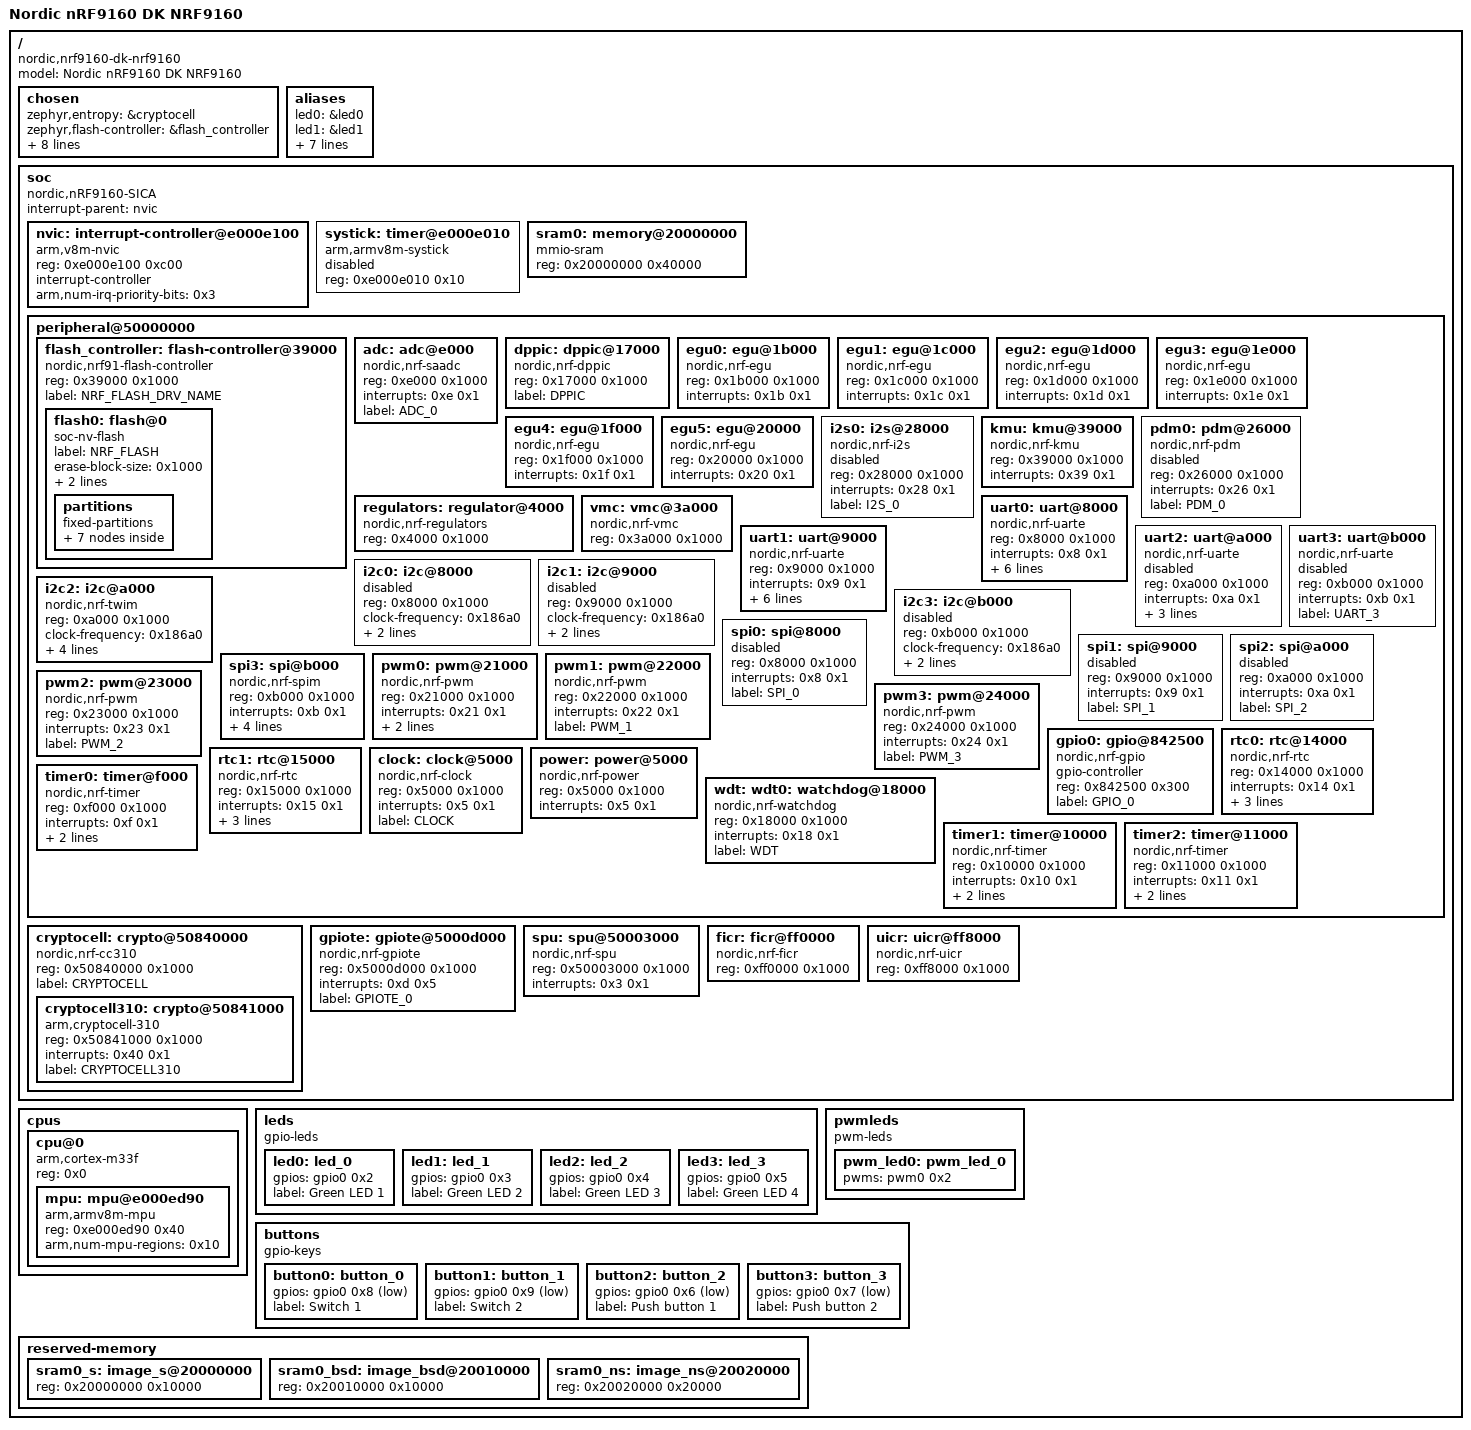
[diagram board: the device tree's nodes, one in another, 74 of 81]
/dts-v1/;

/ {
	#address-cells = < 0x1 >;
	#size-cells = < 0x1 >;
	model = "Nordic nRF9160 DK NRF9160";
	compatible = "nordic,nrf9160-dk-nrf9160";
	chosen {
		zephyr,entropy = &cryptocell;
		zephyr,flash-controller = &flash_controller;
		zephyr,console = &uart0;
		zephyr,shell-uart = &uart0;
		zephyr,uart-mcumgr = &uart0;
		zephyr,sram = &sram0_s;
		zephyr,flash = &flash0;
		zephyr,code-partition = &slot0_partition;
		zephyr,sram-secure-partition = &sram0_s;
		zephyr,sram-non-secure-partition = &sram0_ns;
	};
	aliases {
		led0 = &led0;
		led1 = &led1;
		led2 = &led2;
		led3 = &led3;
		pwm-led0 = &pwm_led0;
		sw0 = &button2;
		sw1 = &button3;
		sw2 = &button0;
		sw3 = &button1;
	};
	soc {
		#address-cells = < 0x1 >;
		#size-cells = < 0x1 >;
		compatible = "nordic,nRF9160-SICA", "nordic,nRF9160", "nordic,nRF91", "simple-bus";
		interrupt-parent = < &nvic >;
		ranges;
		nvic: interrupt-controller@e000e100 {
			compatible = "arm,v8m-nvic";
			reg = < 0xe000e100 0xc00 >;
			interrupt-controller;
			#interrupt-cells = < 0x2 >;
			arm,num-irq-priority-bits = < 0x3 >;
			phandle = < 0x1 >;
		};
		systick: timer@e000e010 {
			compatible = "arm,armv8m-systick";
			reg = < 0xe000e010 0x10 >;
			status = "disabled";
		};
		sram0: memory@20000000 {
			compatible = "mmio-sram";
			reg = < 0x20000000 0x40000 >;
		};
		peripheral@50000000 {
			#address-cells = < 0x1 >;
			#size-cells = < 0x1 >;
			ranges = < 0x0 0x50000000 0x10000000 >;
			flash_controller: flash-controller@39000 {
				compatible = "nordic,nrf91-flash-controller";
				reg = < 0x39000 0x1000 >;
				#address-cells = < 0x1 >;
				#size-cells = < 0x1 >;
				label = "NRF_FLASH_DRV_NAME";
				flash0: flash@0 {
					compatible = "soc-nv-flash";
					label = "NRF_FLASH";
					erase-block-size = < 0x1000 >;
					write-block-size = < 0x4 >;
					reg = < 0x0 0x100000 >;
					partitions {
						compatible = "fixed-partitions";
						#address-cells = < 0x1 >;
						#size-cells = < 0x1 >;
						boot_partition: partition@0 {
							label = "mcuboot";
							reg = < 0x0 0x10000 >;
						};
						slot0_partition: partition@10000 {
							label = "image-0";
							reg = < 0x10000 0x40000 >;
						};
						slot0_ns_partition: partition@50000 {
							label = "image-0-nonsecure";
							reg = < 0x50000 0x30000 >;
						};
						slot1_partition: partition@80000 {
							label = "image-1";
							reg = < 0x80000 0x40000 >;
						};
						slot1_ns_partition: partition@c0000 {
							label = "image-1-nonsecure";
							reg = < 0xc0000 0x30000 >;
						};
						scratch_partition: partition@f0000 {
							label = "image-scratch";
							reg = < 0xf0000 0xa000 >;
						};
						storage_partition: partition@fa000 {
							label = "storage";
							reg = < 0xfa000 0x6000 >;
						};
					};
				};
			};
			adc: adc@e000 {
				compatible = "nordic,nrf-saadc";
				reg = < 0xe000 0x1000 >;
				interrupts = < 0xe 0x1 >;
				status = "okay";
				label = "ADC_0";
				#io-channel-cells = < 0x1 >;
			};
			dppic: dppic@17000 {
				compatible = "nordic,nrf-dppic";
				reg = < 0x17000 0x1000 >;
				status = "okay";
				label = "DPPIC";
			};
			egu0: egu@1b000 {
				compatible = "nordic,nrf-egu";
				reg = < 0x1b000 0x1000 >;
				interrupts = < 0x1b 0x1 >;
				status = "okay";
			};
			egu1: egu@1c000 {
				compatible = "nordic,nrf-egu";
				reg = < 0x1c000 0x1000 >;
				interrupts = < 0x1c 0x1 >;
				status = "okay";
			};
			egu2: egu@1d000 {
				compatible = "nordic,nrf-egu";
				reg = < 0x1d000 0x1000 >;
				interrupts = < 0x1d 0x1 >;
				status = "okay";
			};
			egu3: egu@1e000 {
				compatible = "nordic,nrf-egu";
				reg = < 0x1e000 0x1000 >;
				interrupts = < 0x1e 0x1 >;
				status = "okay";
			};
			egu4: egu@1f000 {
				compatible = "nordic,nrf-egu";
				reg = < 0x1f000 0x1000 >;
				interrupts = < 0x1f 0x1 >;
				status = "okay";
			};
			egu5: egu@20000 {
				compatible = "nordic,nrf-egu";
				reg = < 0x20000 0x1000 >;
				interrupts = < 0x20 0x1 >;
				status = "okay";
			};
			i2s0: i2s@28000 {
				compatible = "nordic,nrf-i2s";
				#address-cells = < 0x1 >;
				#size-cells = < 0x0 >;
				reg = < 0x28000 0x1000 >;
				interrupts = < 0x28 0x1 >;
				status = "disabled";
				label = "I2S_0";
			};
			kmu: kmu@39000 {
				compatible = "nordic,nrf-kmu";
				reg = < 0x39000 0x1000 >;
				interrupts = < 0x39 0x1 >;
				status = "okay";
			};
			pdm0: pdm@26000 {
				compatible = "nordic,nrf-pdm";
				reg = < 0x26000 0x1000 >;
				interrupts = < 0x26 0x1 >;
				status = "disabled";
				label = "PDM_0";
			};
			regulators: regulator@4000 {
				compatible = "nordic,nrf-regulators";
				reg = < 0x4000 0x1000 >;
				status = "okay";
			};
			vmc: vmc@3a000 {
				compatible = "nordic,nrf-vmc";
				reg = < 0x3a000 0x1000 >;
				status = "okay";
			};
			uart0: uart@8000 {
				compatible = "nordic,nrf-uarte";
				reg = < 0x8000 0x1000 >;
				interrupts = < 0x8 0x1 >;
				status = "okay";
				label = "UART_0";
				current-speed = < 0x1c200 >;
				tx-pin = < 0x1d >;
				rx-pin = < 0x1c >;
				rts-pin = < 0x1b >;
				cts-pin = < 0x1a >;
			};
			uart1: uart@9000 {
				compatible = "nordic,nrf-uarte";
				reg = < 0x9000 0x1000 >;
				interrupts = < 0x9 0x1 >;
				status = "okay";
				label = "UART_1";
				current-speed = < 0x1c200 >;
				tx-pin = < 0x1 >;
				rx-pin = < 0x0 >;
				rts-pin = < 0xe >;
				cts-pin = < 0xf >;
			};
			uart2: uart@a000 {
				compatible = "nordic,nrf-uarte";
				reg = < 0xa000 0x1000 >;
				interrupts = < 0xa 0x1 >;
				status = "disabled";
				label = "UART_2";
				tx-pin = < 0x18 >;
				rx-pin = < 0x17 >;
			};
			uart3: uart@b000 {
				compatible = "nordic,nrf-uarte";
				reg = < 0xb000 0x1000 >;
				interrupts = < 0xb 0x1 >;
				status = "disabled";
				label = "UART_3";
			};
			i2c0: i2c@8000 {
				#address-cells = < 0x1 >;
				#size-cells = < 0x0 >;
				reg = < 0x8000 0x1000 >;
				clock-frequency = < 0x186a0 >;
				interrupts = < 0x8 0x1 >;
				status = "disabled";
				label = "I2C_0";
			};
			i2c1: i2c@9000 {
				#address-cells = < 0x1 >;
				#size-cells = < 0x0 >;
				reg = < 0x9000 0x1000 >;
				clock-frequency = < 0x186a0 >;
				interrupts = < 0x9 0x1 >;
				status = "disabled";
				label = "I2C_1";
			};
			i2c2: i2c@a000 {
				#address-cells = < 0x1 >;
				#size-cells = < 0x0 >;
				reg = < 0xa000 0x1000 >;
				clock-frequency = < 0x186a0 >;
				interrupts = < 0xa 0x1 >;
				status = "okay";
				label = "I2C_2";
				compatible = "nordic,nrf-twim";
				sda-pin = < 0x1e >;
				scl-pin = < 0x1f >;
			};
			i2c3: i2c@b000 {
				#address-cells = < 0x1 >;
				#size-cells = < 0x0 >;
				reg = < 0xb000 0x1000 >;
				clock-frequency = < 0x186a0 >;
				interrupts = < 0xb 0x1 >;
				status = "disabled";
				label = "I2C_3";
			};
			spi0: spi@8000 {
				#address-cells = < 0x1 >;
				#size-cells = < 0x0 >;
				reg = < 0x8000 0x1000 >;
				interrupts = < 0x8 0x1 >;
				status = "disabled";
				label = "SPI_0";
			};
			spi1: spi@9000 {
				#address-cells = < 0x1 >;
				#size-cells = < 0x0 >;
				reg = < 0x9000 0x1000 >;
				interrupts = < 0x9 0x1 >;
				status = "disabled";
				label = "SPI_1";
			};
			spi2: spi@a000 {
				#address-cells = < 0x1 >;
				#size-cells = < 0x0 >;
				reg = < 0xa000 0x1000 >;
				interrupts = < 0xa 0x1 >;
				status = "disabled";
				label = "SPI_2";
			};
			spi3: spi@b000 {
				#address-cells = < 0x1 >;
				#size-cells = < 0x0 >;
				reg = < 0xb000 0x1000 >;
				interrupts = < 0xb 0x1 >;
				status = "okay";
				label = "SPI_3";
				compatible = "nordic,nrf-spim";
				sck-pin = < 0x13 >;
				mosi-pin = < 0x12 >;
				miso-pin = < 0x11 >;
			};
			pwm0: pwm@21000 {
				compatible = "nordic,nrf-pwm";
				reg = < 0x21000 0x1000 >;
				interrupts = < 0x21 0x1 >;
				status = "okay";
				label = "PWM_0";
				#pwm-cells = < 0x1 >;
				ch0-pin = < 0x2 >;
				phandle = < 0x3 >;
			};
			pwm1: pwm@22000 {
				compatible = "nordic,nrf-pwm";
				reg = < 0x22000 0x1000 >;
				interrupts = < 0x22 0x1 >;
				status = "okay";
				label = "PWM_1";
				#pwm-cells = < 0x1 >;
			};
			pwm2: pwm@23000 {
				compatible = "nordic,nrf-pwm";
				reg = < 0x23000 0x1000 >;
				interrupts = < 0x23 0x1 >;
				status = "okay";
				label = "PWM_2";
				#pwm-cells = < 0x1 >;
			};
			pwm3: pwm@24000 {
				compatible = "nordic,nrf-pwm";
				reg = < 0x24000 0x1000 >;
				interrupts = < 0x24 0x1 >;
				status = "okay";
				label = "PWM_3";
				#pwm-cells = < 0x1 >;
			};
			gpio0: gpio@842500 {
				compatible = "nordic,nrf-gpio";
				gpio-controller;
				reg = < 0x842500 0x300 >;
				#gpio-cells = < 0x2 >;
				label = "GPIO_0";
				status = "okay";
				phandle = < 0x2 >;
			};
			rtc0: rtc@14000 {
				compatible = "nordic,nrf-rtc";
				reg = < 0x14000 0x1000 >;
				interrupts = < 0x14 0x1 >;
				status = "okay";
				clock-frequency = < 0x8000 >;
				prescaler = < 0x1 >;
				label = "RTC_0";
			};
			rtc1: rtc@15000 {
				compatible = "nordic,nrf-rtc";
				reg = < 0x15000 0x1000 >;
				interrupts = < 0x15 0x1 >;
				status = "okay";
				clock-frequency = < 0x8000 >;
				prescaler = < 0x1 >;
				label = "RTC_1";
			};
			clock: clock@5000 {
				compatible = "nordic,nrf-clock";
				reg = < 0x5000 0x1000 >;
				interrupts = < 0x5 0x1 >;
				status = "okay";
				label = "CLOCK";
			};
			power: power@5000 {
				compatible = "nordic,nrf-power";
				reg = < 0x5000 0x1000 >;
				interrupts = < 0x5 0x1 >;
				status = "okay";
			};
			wdt: wdt0: watchdog@18000 {
				compatible = "nordic,nrf-watchdog";
				reg = < 0x18000 0x1000 >;
				interrupts = < 0x18 0x1 >;
				status = "okay";
				label = "WDT";
			};
			timer0: timer@f000 {
				compatible = "nordic,nrf-timer";
				status = "okay";
				reg = < 0xf000 0x1000 >;
				interrupts = < 0xf 0x1 >;
				prescaler = < 0x0 >;
				label = "TIMER_0";
			};
			timer1: timer@10000 {
				compatible = "nordic,nrf-timer";
				status = "okay";
				reg = < 0x10000 0x1000 >;
				interrupts = < 0x10 0x1 >;
				prescaler = < 0x0 >;
				label = "TIMER_1";
			};
			timer2: timer@11000 {
				compatible = "nordic,nrf-timer";
				status = "okay";
				reg = < 0x11000 0x1000 >;
				interrupts = < 0x11 0x1 >;
				prescaler = < 0x0 >;
				label = "TIMER_2";
			};
		};
		cryptocell: crypto@50840000 {
			compatible = "nordic,nrf-cc310";
			reg = < 0x50840000 0x1000 >;
			label = "CRYPTOCELL";
			status = "okay";
			#address-cells = < 0x1 >;
			#size-cells = < 0x1 >;
			cryptocell310: crypto@50841000 {
				compatible = "arm,cryptocell-310";
				reg = < 0x50841000 0x1000 >;
				interrupts = < 0x40 0x1 >;
				label = "CRYPTOCELL310";
			};
		};
		gpiote: gpiote@5000d000 {
			compatible = "nordic,nrf-gpiote";
			reg = < 0x5000d000 0x1000 >;
			interrupts = < 0xd 0x5 >;
			status = "okay";
			label = "GPIOTE_0";
		};
		spu: spu@50003000 {
			compatible = "nordic,nrf-spu";
			reg = < 0x50003000 0x1000 >;
			interrupts = < 0x3 0x1 >;
			status = "okay";
		};
		ficr: ficr@ff0000 {
			compatible = "nordic,nrf-ficr";
			reg = < 0xff0000 0x1000 >;
			status = "okay";
		};
		uicr: uicr@ff8000 {
			compatible = "nordic,nrf-uicr";
			reg = < 0xff8000 0x1000 >;
			status = "okay";
		};
	};
	cpus {
		#address-cells = < 0x1 >;
		#size-cells = < 0x0 >;
		cpu@0 {
			device_type = "cpu";
			compatible = "arm,cortex-m33f";
			reg = < 0x0 >;
			#address-cells = < 0x1 >;
			#size-cells = < 0x1 >;
			mpu: mpu@e000ed90 {
				compatible = "arm,armv8m-mpu";
				reg = < 0xe000ed90 0x40 >;
				arm,num-mpu-regions = < 0x10 >;
			};
		};
	};
	leds {
		compatible = "gpio-leds";
		led0: led_0 {
			gpios = < &gpio0 0x2 0x0 >;
			label = "Green LED 1";
		};
		led1: led_1 {
			gpios = < &gpio0 0x3 0x0 >;
			label = "Green LED 2";
		};
		led2: led_2 {
			gpios = < &gpio0 0x4 0x0 >;
			label = "Green LED 3";
		};
		led3: led_3 {
			gpios = < &gpio0 0x5 0x0 >;
			label = "Green LED 4";
		};
	};
	pwmleds {
		compatible = "pwm-leds";
		pwm_led0: pwm_led_0 {
			pwms = < &pwm0 0x2 >;
		};
	};
	buttons {
		compatible = "gpio-keys";
		button0: button_0 {
			gpios = < &gpio0 0x8 0x11 >;
			label = "Switch 1";
		};
		button1: button_1 {
			gpios = < &gpio0 0x9 0x11 >;
			label = "Switch 2";
		};
		button2: button_2 {
			gpios = < &gpio0 0x6 0x11 >;
			label = "Push button 1";
		};
		button3: button_3 {
			gpios = < &gpio0 0x7 0x11 >;
			label = "Push button 2";
		};
	};
	reserved-memory {
		#address-cells = < 0x1 >;
		#size-cells = < 0x1 >;
		ranges;
		sram0_s: image_s@20000000 {
			reg = < 0x20000000 0x10000 >;
		};
		sram0_bsd: image_bsd@20010000 {
			reg = < 0x20010000 0x10000 >;
		};
		sram0_ns: image_ns@20020000 {
			reg = < 0x20020000 0x20000 >;
		};
	};
};
